# HC32F558 register map
File version: 1.0
CPU: CM4 r0p1, little endian, MPU, FPU, 4 interrupt priority bits
Registers are 32-bit, read-write, reset 0x0 unless marked. A register's access mark holds for its fields unless they carry their own. Offsets are from the block's base; [hi:lo] are bit positions; {n}, {i} and the like mark numbered series; 'fields as' and 'values as' point back to an identical list.

## HRPWM_COMMON
Base 0x40036800
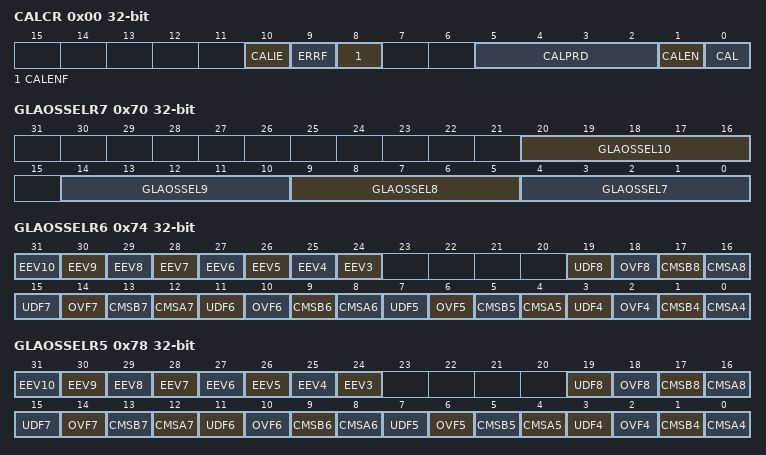
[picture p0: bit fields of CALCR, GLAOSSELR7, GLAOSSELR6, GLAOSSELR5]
0x00 CALCR
  [10] CALIE, [9] ERRF, [8] CALENF, [5:2] CALPRD, [1] CALEN, [0] CAL
0x70 GLAOSSELR7
  [20:16] GLAOSSEL10, [14:10] GLAOSSEL9, [9:5] GLAOSSEL8, [4:0] GLAOSSEL7
0x74 GLAOSSELR6
  [n+21] EEV{n} (n=3..10), [4n-13] UDF{n} (n=4..8), [4n-14] OVF{n} (n=4..8), [4n-15] CMSB{n} (n=4..8), [4n-16] CMSA{n} (n=4..8)
0x78 GLAOSSELR5
  fields as GLAOSSELR6
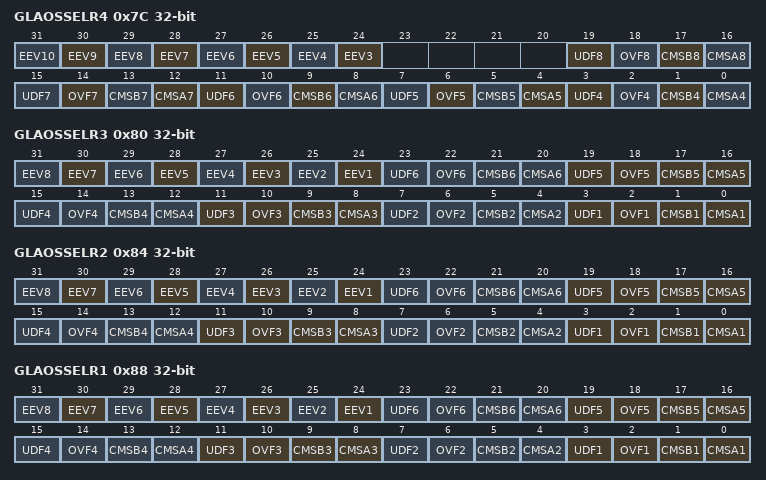
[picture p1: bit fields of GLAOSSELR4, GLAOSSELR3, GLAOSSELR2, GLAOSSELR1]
0x7C GLAOSSELR4
  fields as GLAOSSELR6
0x80 GLAOSSELR3
  [n+23] EEV{n} (n=1..8), [4n-1] UDF{n} (n=1..6), [4n-2] OVF{n} (n=1..6), [4n-3] CMSB{n} (n=1..6), [4n-4] CMSA{n} (n=1..6)
0x84 GLAOSSELR2
  fields as GLAOSSELR3
0x88 GLAOSSELR1
  fields as GLAOSSELR3
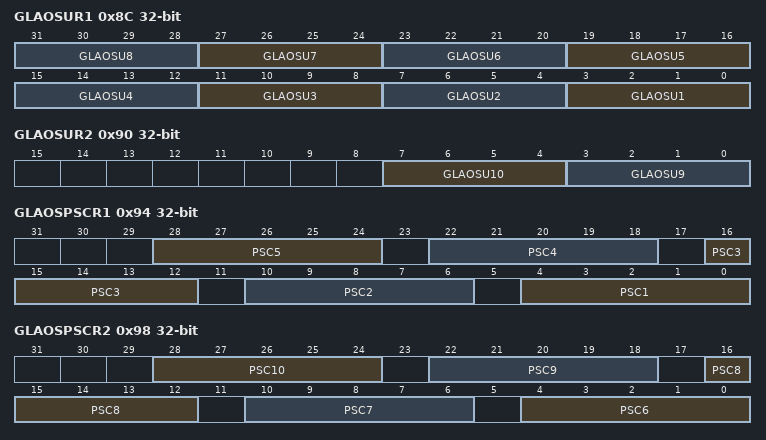
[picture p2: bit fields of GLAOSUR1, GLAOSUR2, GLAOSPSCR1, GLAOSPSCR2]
0x8C GLAOSUR1
  [4n-1:4n-4] GLAOSU{n} (n=1..8)
0x90 GLAOSUR2
  [7:4] GLAOSU10, [3:0] GLAOSU9
0x94 GLAOSPSCR1
  [6n-2:6n-6] PSC{n} (n=1..5)
0x98 GLAOSPSCR2
  [6n-32:6n-36] PSC{n} (n=6..10)
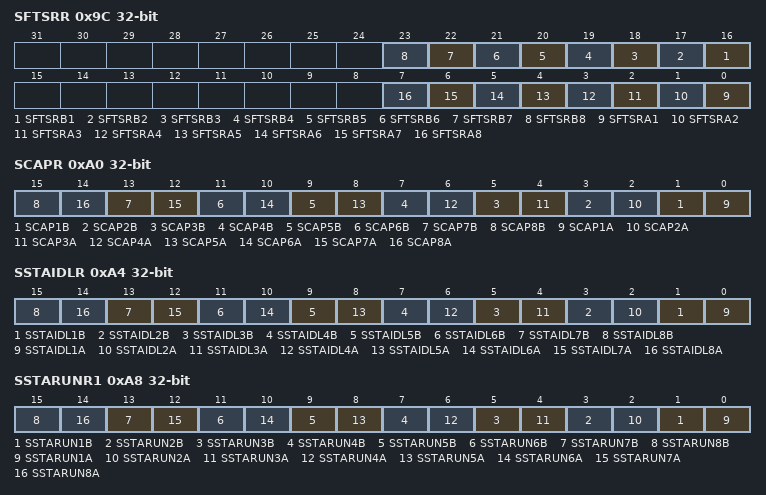
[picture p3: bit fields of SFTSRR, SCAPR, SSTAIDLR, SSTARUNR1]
0x9C SFTSRR wo
  [n+15] SFTSRB{n} (n=1..8), [n-1] SFTSRA{n} (n=1..8)
0xA0 SCAPR wo
  [2n-1] SCAP{n}B (n=1..8), [2n-2] SCAP{n}A (n=1..8)
0xA4 SSTAIDLR wo
  [2n-1] SSTAIDL{n}B (n=1..8), [2n-2] SSTAIDL{n}A (n=1..8)
0xA8 SSTARUNR1
  [2n-1] SSTARUN{n}B (n=1..8), [2n-2] SSTARUN{n}A (n=1..8)
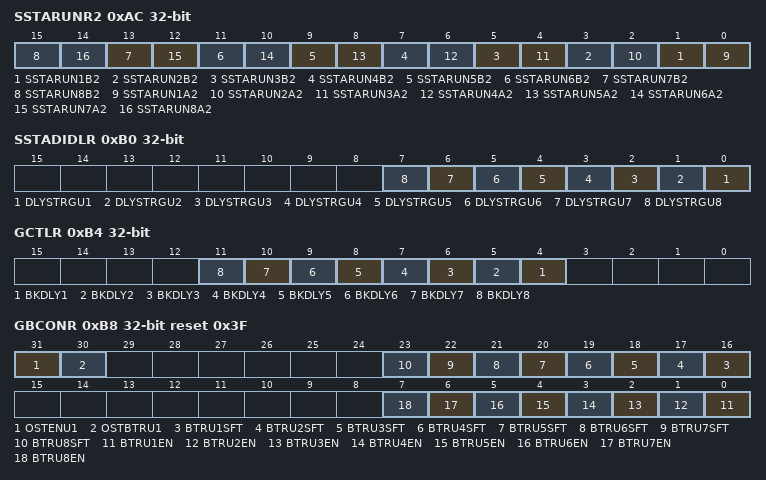
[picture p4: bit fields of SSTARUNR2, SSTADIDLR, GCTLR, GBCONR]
0xAC SSTARUNR2 wo
  [2n-1] SSTARUN{n}B2 (n=1..8), [2n-2] SSTARUN{n}A2 (n=1..8)
0xB0 SSTADIDLR
  [n-1] DLYSTRGU{n} (n=1..8)
0xB4 GCTLR
  [n+3] BKDLY{n} (n=1..8)
0xB8 GBCONR reset 0x3F
  [31] OSTENU1, [30] OSTBTRU1, [n+15] BTRU{n}SFT wo (n=1..8), [n-1] BTRU{n}EN (n=1..8)
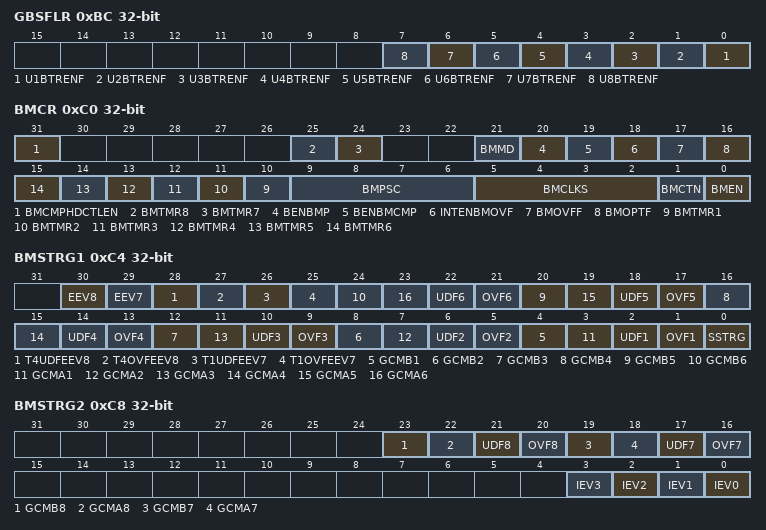
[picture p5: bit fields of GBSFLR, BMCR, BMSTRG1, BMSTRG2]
0xBC GBSFLR
  [n-1] U{n}BTRENF (n=1..8)
0xC0 BMCR
  [31] BMCMPHDCTLEN, [25] BMTMR8, [24] BMTMR7, [21] BMMD, [20] BENBMP, [19] BENBMCMP, [18] INTENBMOVF, [17] BMOVFF, [16] BMOPTF, [n+9] BMTMR{n} (n=1..6), [9:6] BMPSC, [5:2] BMCLKS, [1] BMCTN, [0] BMEN
0xC4 BMSTRG1
  [30] EEV8, [29] EEV7, [28] T4UDFEEV8, [27] T4OVFEEV8, [26] T1UDFEEV7, [25] T1OVFEEV7, [4n] GCMB{n} (n=1..6), [4n-1] GCMA{n} (n=1..6), [4n-2] UDF{n} (n=1..6), [4n-3] OVF{n} (n=1..6), [0] SSTRG
0xC8 BMSTRG2
  [23] GCMB8, [22] GCMA8, [21] UDF8, [20] OVF8, [19] GCMB7, [18] GCMA7, [17] UDF7, [16] OVF7, [n] IEV{n} (n=0..3)
0xCC BMPERAR
  [15:0] BMPERAR
0xD0 BMPERBR
  [15:0] BMPERBR
0xD4 BMCMAR
  [15:0] BMCMAR
0xD8 BMCMBR
  [15:0] BMCMBR
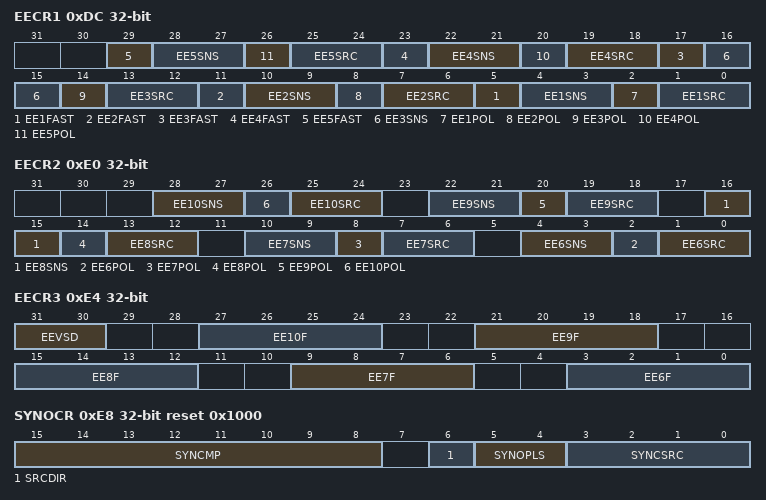
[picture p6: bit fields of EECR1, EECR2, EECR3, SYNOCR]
0xDC EECR1
  [6n-1] EE{n}FAST (n=1..5), [6n-2:6n-3] EE{n}SNS (n=1..5), [6n-4] EE{n}POL (n=1..5), [6n-5:6n-6] EE{n}SRC (n=1..5)
0xE0 EECR2
  [6n-32:6n-33] EE{n}SNS (n=6..10), [6n-34] EE{n}POL (n=6..10), [6n-35:6n-36] EE{n}SRC (n=6..10)
0xE4 EECR3
  [31:30] EEVSD, [6n-33:6n-36] EE{n}F (n=6..10)
0xE8 SYNOCR reset 0x1000
  [15:8] SYNCMP, [6] SRCDIR, [5:4] SYNOPLS, [3:0] SYNCSRC
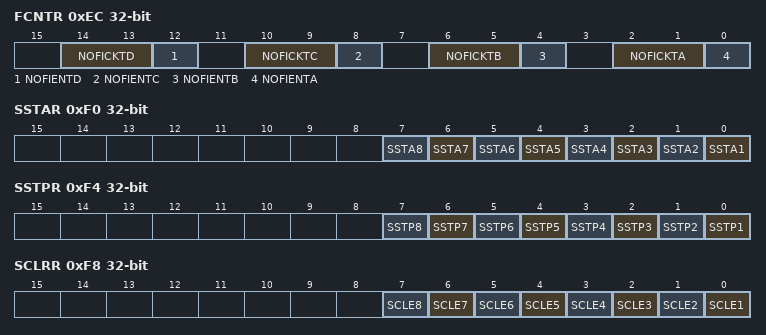
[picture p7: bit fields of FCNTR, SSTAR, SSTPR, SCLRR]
0xEC FCNTR
  [14:13] NOFICKTD, [12] NOFIENTD, [10:9] NOFICKTC, [8] NOFIENTC, [6:5] NOFICKTB, [4] NOFIENTB, [2:1] NOFICKTA, [0] NOFIENTA
0xF0 SSTAR
  [n-1] SSTA{n} (n=1..8)
0xF4 SSTPR wo
  [n-1] SSTP{n} (n=1..8)
0xF8 SCLRR wo
  [n-1] SCLE{n} (n=1..8)
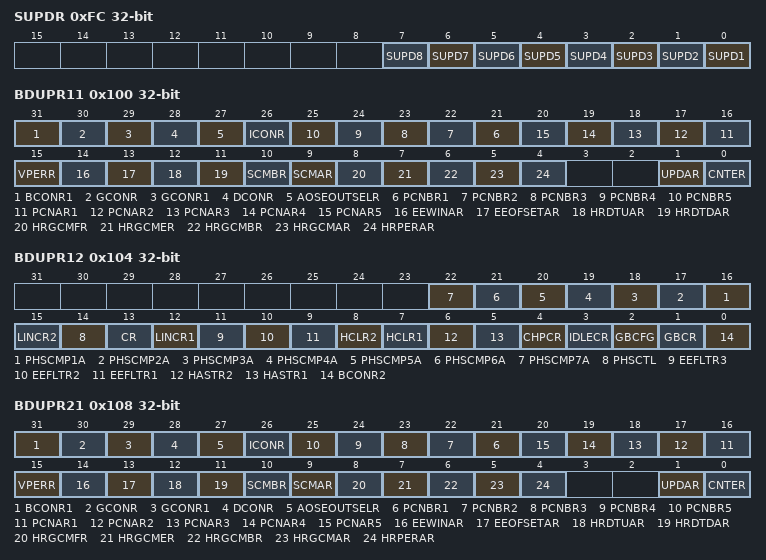
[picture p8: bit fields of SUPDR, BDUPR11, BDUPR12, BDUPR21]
0xFC SUPDR wo
  [n-1] SUPD{n} (n=1..8)
0x100 BDUPR11
  [31] BCONR1, [30] GCONR, [29] GCONR1, [28] DCONR, [27] AOSEOUTSELR, [26] ICONR, [n+20] PCNBR{n} (n=1..5), [n+15] PCNAR{n} (n=1..5), [15] VPERR, [14] EEWINAR, [13] EEOFSETAR, [12] HRDTUAR, [11] HRDTDAR, [10] SCMBR, [9] SCMAR, [8] HRGCMFR, [7] HRGCMER, [6] HRGCMBR, [5] HRGCMAR, [4] HRPERAR, [1] UPDAR, [0] CNTER
0x104 BDUPR12
  [n+15] PHSCMP{n}A (n=1..7), [15] LINCR2, [14] PHSCTL, [13] CR, [12] LINCR1, [11] EEFLTR3, [10] EEFLTR2, [9] EEFLTR1, [8] HCLR2, [7] HCLR1, [6] HASTR2, [5] HASTR1, [4] CHPCR, [3] IDLECR, [2] GBCFG, [1] GBCR, [0] BCONR2
0x108 BDUPR21
  fields as BDUPR11
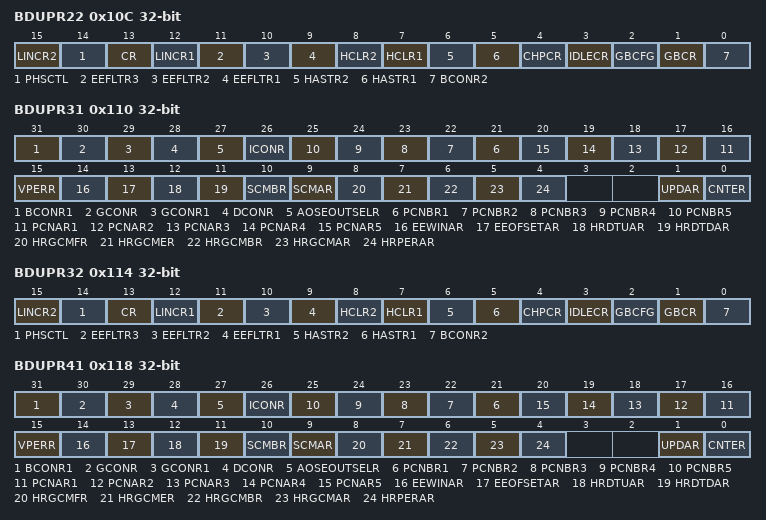
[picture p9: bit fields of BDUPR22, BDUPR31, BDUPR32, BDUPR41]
0x10C BDUPR22
  [15] LINCR2, [14] PHSCTL, [13] CR, [12] LINCR1, [11] EEFLTR3, [10] EEFLTR2, [9] EEFLTR1, [8] HCLR2, [7] HCLR1, [6] HASTR2, [5] HASTR1, [4] CHPCR, [3] IDLECR, [2] GBCFG, [1] GBCR, [0] BCONR2
0x110 BDUPR31
  fields as BDUPR11
0x114 BDUPR32
  fields as BDUPR22
0x118 BDUPR41
  fields as BDUPR11
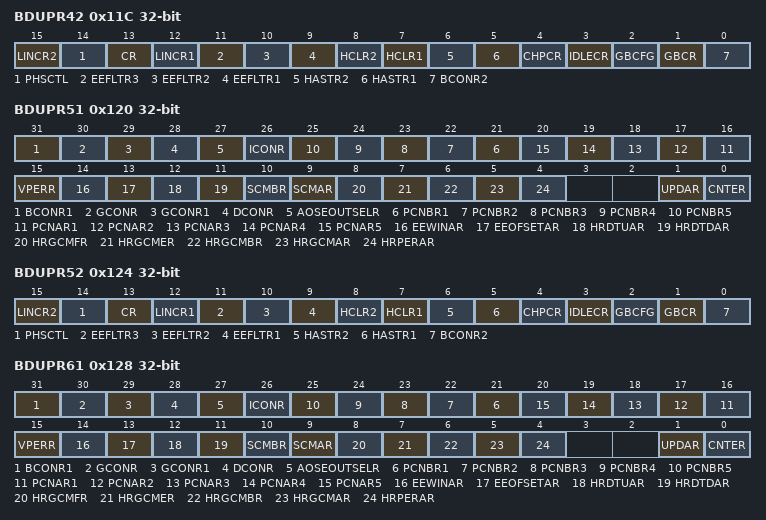
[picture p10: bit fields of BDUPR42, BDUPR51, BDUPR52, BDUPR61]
0x11C BDUPR42
  fields as BDUPR22
0x120 BDUPR51
  fields as BDUPR11
0x124 BDUPR52
  fields as BDUPR22
0x128 BDUPR61
  fields as BDUPR11
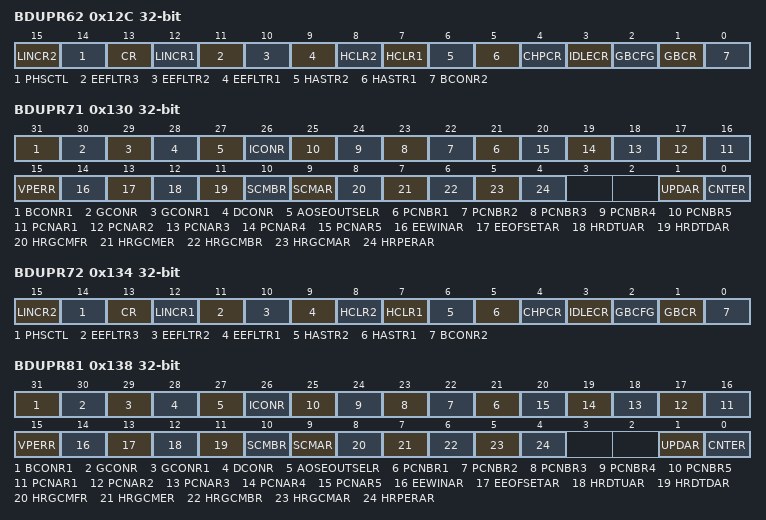
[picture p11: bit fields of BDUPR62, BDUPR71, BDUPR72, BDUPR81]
0x12C BDUPR62
  fields as BDUPR22
0x130 BDUPR71
  fields as BDUPR11
0x134 BDUPR72
  fields as BDUPR22
0x138 BDUPR81
  fields as BDUPR11
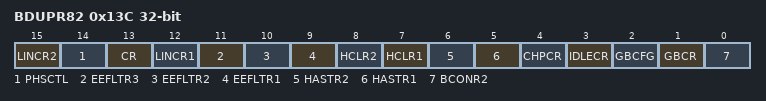
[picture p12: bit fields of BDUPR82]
0x13C BDUPR82
  fields as BDUPR22
0x148 BDMADR
